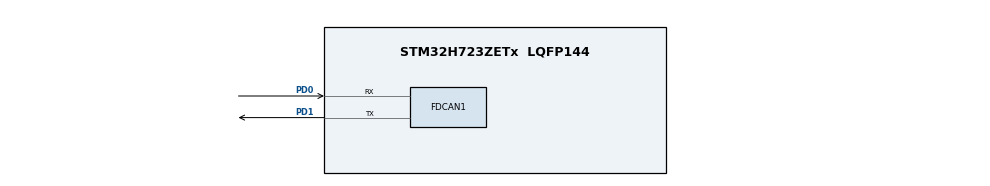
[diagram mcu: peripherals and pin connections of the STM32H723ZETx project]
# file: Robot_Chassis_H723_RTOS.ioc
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CORTEX_M7.default_mode_Activation=1
FDCAN1.AutoRetransmission=ENABLE
FDCAN1.CalculateBaudRateNominal=999999
FDCAN1.CalculateTimeBitNominal=1000
FDCAN1.CalculateTimeQuantumNominal=45.45454545454546
FDCAN1.NominalPrescaler=5
FDCAN1.NominalTimeSeg1=16
FDCAN1.NominalTimeSeg2=5
FDCAN1.RxFifo0ElmtsNbr=0
FDCAN1.RxFifo1ElmtsNbr=8
FDCAN1.StdFiltersNbr=1
FDCAN1.TxFifoQueueElmtsNbr=8
FREERTOS.Queues01=CanRxQueue,16,CanRxMessage_t,0,Dynamic,NULL,NULL
FREERTOS.Tasks01=defaultTask,24,256,StartDefaultTask,Default,NULL,Dynamic,NULL,NULL;CanRxTask,40,512,StartCanRxTask,Default,NULL,Dynamic,NULL,NULL;MotorControlTas,32,512,StartMotorControlTask,Default,NULL,Dynamic,NULL,NULL
Mcu.Family=STM32H7
Mcu.Name=STM32H723ZETx
Mcu.Package=LQFP144
NVIC.FDCAN1_IT0_IRQn=true\:5\:0\:false\:false\:true\:true\:true\:true\:true
NVIC.PriorityGroup=NVIC_PRIORITYGROUP_4
NVIC.RCC_IRQn=true\:5\:0\:false\:false\:true\:true\:true\:false\:true
NVIC.TIM7_IRQn=true\:15\:0\:false\:false\:true\:false\:false\:true\:true
NVIC.TimeBase=TIM7_IRQn
NVIC.TimeBaseIP=TIM7
PD0.Mode=FDCAN_Activate
PD0.Signal=FDCAN1_RX
PD1.Mode=FDCAN_Activate
PD1.Signal=FDCAN1_TX
PH0-OSC_IN.Mode=HSE-External-Oscillator
PH0-OSC_IN.Signal=RCC_OSC_IN
PH1-OSC_OUT.Mode=HSE-External-Oscillator
PH1-OSC_OUT.Signal=RCC_OSC_OUT
ProjectManager.HeapSize=0x200
ProjectManager.StackSize=0x400
ProjectManager.TargetToolchain=CMake
RCC.ADCFreq_Value=16125000
RCC.APB1Freq_Value=137500000
RCC.APB2Freq_Value=137500000
RCC.APB3Freq_Value=137500000
RCC.APB4Freq_Value=137500000
RCC.CortexFreq_Value=550000000
RCC.D1PPRE=RCC_APB3_DIV2
RCC.D2PPRE1=RCC_APB1_DIV2
RCC.D2PPRE2=RCC_APB2_DIV2
RCC.D3PPRE=RCC_APB4_DIV2
RCC.DIVM1=4
RCC.DIVN1=275
RCC.DIVP1=1
RCC.DIVQ1=5
RCC.HCLKFreq_Value=275000000
RCC.HPRE=RCC_HCLK_DIV2
RCC.HSE_VALUE=8000000
RCC.PLLFRACN=0
RCC.PLLSourceVirtual=RCC_PLLSOURCE_HSE
RCC.SYSCLKFreq_VALUE=550000000
RCC.SYSCLKSource=RCC_SYSCLKSOURCE_PLLCLK
RCC.USBFreq_Value=110000000
VP_FREERTOS_VS_CMSIS_V2.Mode=CMSIS_V2
VP_MEMORYMAP_VS_MEMORYMAP.Mode=CurAppReg
VP_SYS_VS_tim7.Mode=TIM7
board=custom

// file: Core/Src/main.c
/* USER CODE BEGIN Header */
/**
  ******************************************************************************
  * @file           : main.c
  * @brief          : Main program body
  ******************************************************************************
  * @attention
  *
  * Copyright (c) 2026 STMicroelectronics.
  * All rights reserved.
  *
  * This software is licensed under terms that can be found in the LICENSE file
  * in the root directory of this software component.
  * If no LICENSE file comes with this software, it is provided AS-IS.
  *
  ******************************************************************************
  */
/* USER CODE END Header */
#include "main.h"
#include "FreeRTOS.h"
#include "cmsis_os2.h"
#include "fdcan.h"
#include "gpio.h"

/* USER CODE BEGIN Includes */
#include "motor_manager.h"
#include "can_bus.h"
/* USER CODE END Includes */

void SystemClock_Config(void);
static void MPU_Config(void);
void MX_FREERTOS_Init(void);

int main(void)
{

  /* MPU Configuration--------------------------------------------------------*/
  MPU_Config();

  /* MCU Configuration--------------------------------------------------------*/

  /* Reset of all peripherals, Initializes the Flash interface and the Systick. */
  HAL_Init();

  /* Configure the system clock */
  SystemClock_Config();

  /* Initialize all configured peripherals */
  MX_GPIO_Init();
  MX_FDCAN1_Init();
  MotorManager_Init();

  /* Init scheduler */
  osKernelInitialize();  /* Call init function for freertos objects (in cmsis_os2.c) */
  MX_FREERTOS_Init();
  /* Start scheduler */
  osKernelStart();

  /* We should never get here as control is now taken by the scheduler */

  /* Infinite loop */
  while (1)
  {

  }
}

void SystemClock_Config(void)
{
  RCC_OscInitTypeDef RCC_OscInitStruct = {0};
  RCC_ClkInitTypeDef RCC_ClkInitStruct = {0};

  /** Supply configuration update enable
  */
  HAL_PWREx_ConfigSupply(PWR_LDO_SUPPLY);

  /** Configure the main internal regulator output voltage
  */
  __HAL_PWR_VOLTAGESCALING_CONFIG(PWR_REGULATOR_VOLTAGE_SCALE0);

  while(!__HAL_PWR_GET_FLAG(PWR_FLAG_VOSRDY)) {}

  /** Initializes the RCC Oscillators according to the specified parameters
  * in the RCC_OscInitTypeDef structure.
  */
  RCC_OscInitStruct.OscillatorType = RCC_OSCILLATORTYPE_HSE;
  RCC_OscInitStruct.HSEState = RCC_HSE_ON;
  RCC_OscInitStruct.PLL.PLLState = RCC_PLL_ON;
  RCC_OscInitStruct.PLL.PLLSource = RCC_PLLSOURCE_HSE;
  RCC_OscInitStruct.PLL.PLLM = 4;
  RCC_OscInitStruct.PLL.PLLN = 275;
  RCC_OscInitStruct.PLL.PLLP = 1;
  RCC_OscInitStruct.PLL.PLLQ = 5;
  RCC_OscInitStruct.PLL.PLLR = 2;
  RCC_OscInitStruct.PLL.PLLRGE = RCC_PLL1VCIRANGE_1;
  RCC_OscInitStruct.PLL.PLLVCOSEL = RCC_PLL1VCOWIDE;
  RCC_OscInitStruct.PLL.PLLFRACN = 0;
  if (HAL_RCC_OscConfig(&RCC_OscInitStruct) != HAL_OK)
  {
    Error_Handler();
  }

  /** Initializes the CPU, AHB and APB buses clocks
  */
  RCC_ClkInitStruct.ClockType = RCC_CLOCKTYPE_HCLK|RCC_CLOCKTYPE_SYSCLK
                              |RCC_CLOCKTYPE_PCLK1|RCC_CLOCKTYPE_PCLK2
                              |RCC_CLOCKTYPE_D3PCLK1|RCC_CLOCKTYPE_D1PCLK1;
  RCC_ClkInitStruct.SYSCLKSource = RCC_SYSCLKSOURCE_PLLCLK;
  RCC_ClkInitStruct.SYSCLKDivider = RCC_SYSCLK_DIV1;
  RCC_ClkInitStruct.AHBCLKDivider = RCC_HCLK_DIV2;
  RCC_ClkInitStruct.APB3CLKDivider = RCC_APB3_DIV2;
  RCC_ClkInitStruct.APB1CLKDivider = RCC_APB1_DIV2;
  RCC_ClkInitStruct.APB2CLKDivider = RCC_APB2_DIV2;
  RCC_ClkInitStruct.APB4CLKDivider = RCC_APB4_DIV2;

  if (HAL_RCC_ClockConfig(&RCC_ClkInitStruct, FLASH_LATENCY_3) != HAL_OK)
  {
    Error_Handler();
  }
}

 /* MPU Configuration */

void MPU_Config(void)
{
  MPU_Region_InitTypeDef MPU_InitStruct = {0};

  /* Disables the MPU */
  HAL_MPU_Disable();

  /** Initializes and configures the Region and the memory to be protected
  */
  MPU_InitStruct.Enable = MPU_REGION_ENABLE;
  MPU_InitStruct.Number = MPU_REGION_NUMBER0;
  MPU_InitStruct.BaseAddress = 0x0;
  MPU_InitStruct.Size = MPU_REGION_SIZE_4GB;
  MPU_InitStruct.SubRegionDisable = 0x87;
  MPU_InitStruct.TypeExtField = MPU_TEX_LEVEL0;
  MPU_InitStruct.AccessPermission = MPU_REGION_NO_ACCESS;
  MPU_InitStruct.DisableExec = MPU_INSTRUCTION_ACCESS_DISABLE;
  MPU_InitStruct.IsShareable = MPU_ACCESS_SHAREABLE;
  MPU_InitStruct.IsCacheable = MPU_ACCESS_NOT_CACHEABLE;
  MPU_InitStruct.IsBufferable = MPU_ACCESS_NOT_BUFFERABLE;

  HAL_MPU_ConfigRegion(&MPU_InitStruct);
  /* Enables the MPU */
  HAL_MPU_Enable(MPU_PRIVILEGED_DEFAULT);

}

void HAL_TIM_PeriodElapsedCallback(TIM_HandleTypeDef *htim)
{
  if (htim->Instance == TIM7)
  {
    HAL_IncTick();
  }
}

void Error_Handler(void)
{
  __disable_irq();
  while (1)
  {
  }
}

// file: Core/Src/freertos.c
/* USER CODE BEGIN Header */
/**
  ******************************************************************************
  * File Name          : freertos.c
  * Description        : Code for freertos applications
  ******************************************************************************
  * @attention
  *
  * Copyright (c) 2026 STMicroelectronics.
  * All rights reserved.
  *
  * This software is licensed under terms that can be found in the LICENSE file
  * in the root directory of this software component.
  * If no LICENSE file comes with this software, it is provided AS-IS.
  *
  ******************************************************************************
  */
/* USER CODE END Header */

#include "cmsis_os2.h"
#include "FreeRTOS.h"
#include "FreeRTOS.h"
#include "main.h"
#include "task.h"

/* USER CODE BEGIN Includes */
#include "can_bus.h"
#include "m3508.h"
#include "motor_manager.h"
#include "pid.h"
/* USER CODE END Includes */

/* USER CODE BEGIN Variables */
CanRxMessage_t CanRxMessage;
/* USER CODE END Variables */
/* Definitions for defaultTask */
osThreadId_t defaultTaskHandle;
const osThreadAttr_t defaultTask_attributes = {
  .name = "defaultTask",
  .stack_size = 256 * 4,
  .priority = (osPriority_t) osPriorityNormal,
};
/* Definitions for CanRxTask */
osThreadId_t CanRxTaskHandle;
const osThreadAttr_t CanRxTask_attributes = {
  .name = "CanRxTask",
  .stack_size = 512 * 4,
  .priority = (osPriority_t) osPriorityHigh,
};
/* Definitions for MotorControlTas */
osThreadId_t MotorControlTasHandle;
const osThreadAttr_t MotorControlTas_attributes = {
  .name = "MotorControlTas",
  .stack_size = 512 * 4,
  .priority = (osPriority_t) osPriorityAboveNormal,
};
/* Definitions for CanRxQueue */
osMessageQueueId_t CanRxQueueHandle;
const osMessageQueueAttr_t CanRxQueue_attributes = {
  .name = "CanRxQueue"
};

void StartDefaultTask(void *argument);
void StartCanRxTask(void *argument);
void StartMotorControlTask(void *argument);

void MX_FREERTOS_Init(void); /* (MISRA C 2004 rule 8.1) */

void MX_FREERTOS_Init(void) {

  /* Create the queue(s) */
  /* creation of CanRxQueue */
  CanRxQueueHandle = osMessageQueueNew (16, sizeof(CanRxMessage_t), &CanRxQueue_attributes);

  /* Create the thread(s) */
  /* creation of defaultTask */
  defaultTaskHandle = osThreadNew(StartDefaultTask, NULL, &defaultTask_attributes);

  /* creation of CanRxTask */
  CanRxTaskHandle = osThreadNew(StartCanRxTask, NULL, &CanRxTask_attributes);

  /* creation of MotorControlTas */
  MotorControlTasHandle = osThreadNew(StartMotorControlTask, NULL, &MotorControlTas_attributes);

  /* USER CODE BEGIN RTOS_THREADS */
  /* add threads, ... */
  CAN_Init();

  PID_Init(&motor_pid_1, 0, 0, 0, 0.001f, 2000, 2000);
  PID_Init(&motor_pid_2, 0, 0, 0, 0.001f, 2000, 2000);
  PID_Init(&motor_pid_3, 0, 0, 0, 0.001f, 2000, 2000);
  PID_Init(&motor_pid_4, 0, 0, 0, 0.001f, 2000, 2000);

  /* USER CODE END RTOS_THREADS */

}

void StartDefaultTask(void *argument)
{
  for(;;)
  {
    osDelay(1);
  }
}

void StartCanRxTask(void *argument)
{
  /* USER CODE BEGIN StartCanRxTask */
  /* Infinite loop */
  for(;;)
  {
      osStatus_t status = osMessageQueueGet(CanRxQueueHandle, &CanRxMessage, NULL, osWaitForever);
      if (status == osOK) {
          switch (CanRxMessage.id) {
              case 0x201:
                  M3508_UpdateFeedback(&motor_1, CanRxMessage.data);
                  break;
              case 0x202:
                  M3508_UpdateFeedback(&motor_2, CanRxMessage.data);
                  break;
              case 0x203:
                  M3508_UpdateFeedback(&motor_3, CanRxMessage.data);
                  break;
              case 0x204:
                  M3508_UpdateFeedback(&motor_4, CanRxMessage.data);
                  break;
          }
      }
  }
  /* USER CODE END StartCanRxTask */
}

void StartMotorControlTask(void *argument)
{
  /* USER CODE BEGIN StartMotorControlTask */
  uint32_t last_wake_time = osKernelGetTickCount();
  /* Infinite loop */
  for(;;)
  {
    motor_1.targetCurrent = (int16_t)PID_Calculate(&motor_pid_1, motor_1.targetSpeed, motor_1.speed);
    motor_2.targetCurrent = (int16_t)PID_Calculate(&motor_pid_2, motor_2.targetSpeed, motor_2.speed);
    motor_3.targetCurrent = (int16_t)PID_Calculate(&motor_pid_3, motor_3.targetSpeed, motor_3.speed);
    motor_4.targetCurrent = (int16_t)PID_Calculate(&motor_pid_4, motor_4.targetSpeed, motor_4.speed);

    M3508_SendCurrent(&motor_1, &motor_2, &motor_3, &motor_4);

    last_wake_time += 1;
    osDelayUntil(last_wake_time);
  }
  /* USER CODE END StartMotorControlTask */
}
